# MK65F18 register map
Vendor: NXP Semiconductors; Series: Kinetis_K; File version: 1.6
CPU: CM4 r0p1, little endian, no MPU, FPU, VTOR, 4 interrupt priority bits
Registers are 32-bit, read-write, reset 0x0 unless marked. A register's access mark holds for its fields unless they carry their own. Offsets are from the block's base; [hi:lo] are bit positions; {n}, {i} and the like mark numbered series; 'fields as' and 'values as' point back to an identical list.

## DMAMUX — DMA channel multiplexor
Base 0x40021000; register names take the prefix DMAMUX_
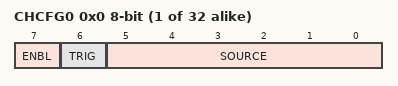
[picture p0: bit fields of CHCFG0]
{0x0+i} CHCFG{i} (i=0..31) 8-bit — Channel Configuration register
  [7] ENBL — DMA Channel Enable
    0=DMA channel is disabled. This mode is primarily used during configuration of the DMAMux. The DMA has separate channel enables/disables, which should be used to disable or reconfigure a DMA channel.; 1=DMA channel is enabled
  [6] TRIG — DMA Channel Trigger Enable
    0=Triggering is disabled. If triggering is disabled and ENBL is set, the DMA Channel will simply route the specified source to the DMA channel. (Normal mode); 1=Triggering is enabled. If triggering is enabled and ENBL is set, the DMAMUX is in Periodic Trigger mode.
  [5:0] SOURCE — DMA Channel Source (Slot)
    0=Disable_Signal; 1=TSI0_Signal; 2=UART0_Rx_Signal; 3=UART0_Tx_Signal; 4=UART1_Rx_Signal; 5=UART1_Tx_Signal; 6=UART2_Rx_Signal; 7=UART2_Tx_Signal; 8=UART3_Rx_Signal; 9=UART3_Tx_Signal; 10=UART4_Signal; 12=I2S0_Rx_Signal; 13=I2S0_Tx_Signal; 14=SPI0_Rx_Signal; 15=SPI0_Tx_Signal; 16=SPI1_Rx_Signal; 17=SPI1_Tx_Signal; 18=I2C0_I2C3_Signal; 19=I2C1_I2C2_Signal; {v}=FTM0_Channel{v-20}_Signal (v=20..27); 28=FTM1_TPM1_Channel0_Signal; 29=FTM1_TPM1_Channel1_Signal; 30=FTM2_TPM2_Channel0_Signal; 31=FTM2_TPM2_Channel1_Signal; {v}=FTM3_Channel{v-32}_Signal (v=32..37); 38=FTM3_Channel6_SPI2_Rx_Signal; 39=FTM3_Channel7_SPI2_Tx_Signal; 40=ADC0_Signal; 41=ADC1_Signal; 42=CMP0_Signal; 43=CMP1_Signal; 44=CMP2_CMP3_Signal; 45=DAC0_Signal; 46=DAC1_Signal; 47=CMT_Signal; 48=PDB_Signal; 49=PortA_Signal; 50=PortB_Signal; 51=PortC_Signal; 52=PortD_Signal; 53=PortE_Signal; 54=IEEE1588Timer0_Signal; 55=IEEE1588Timer1_TPM1_Overflow_Signal; 56=IEEE1588Timer2_TPM2_Overflow_Signal; 57=IEEE1588Timer3_Signal; 58=LPUART0_Rx_Signal; 59=LPUART0_Tx_Signal; {v}=AlwaysOn{v}_Signal (v=60..63)

## CRC — Cyclic Redundancy Check
Base 0x40032000; register names take the prefix CRC_
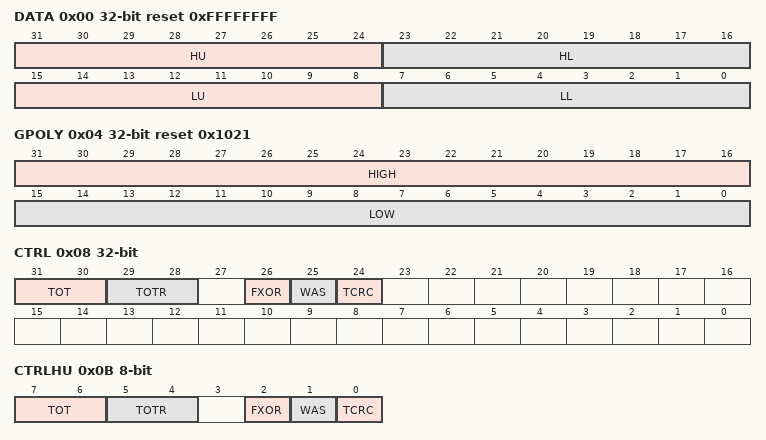
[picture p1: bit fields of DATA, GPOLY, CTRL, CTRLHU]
0x00 DATA reset 0xFFFFFFFF (CRC view) — CRC Data register
  [31:24] HU — CRC High Upper Byte
  [23:16] HL — CRC High Lower Byte
  [15:8] LU — CRC Low Upper Byte
  [7:0] LL — CRC Low Lower Byte
0x00 DATAL 16-bit reset 0xFFFF (CRC view) — CRC_DATAL register.
  [15:0] DATAL — DATAL stores the lower 16 bits of the 16/32 bit CRC
0x00 DATALL 8-bit reset 0xFF (CRC view) — CRC_DATALL register.
  [7:0] DATALL — CRCLL stores the first 8 bits of the 32 bit DATA
0x01 DATALU 8-bit reset 0xFF — CRC_DATALU register.
  [7:0] DATALU — DATALL stores the second 8 bits of the 32 bit CRC
0x02 DATAH 16-bit reset 0xFFFF (CRC view) — CRC_DATAH register.
  [15:0] DATAH — DATAH stores the high 16 bits of the 16/32 bit CRC
0x02 DATAHL 8-bit reset 0xFF (CRC view) — CRC_DATAHL register.
  [7:0] DATAHL — DATAHL stores the third 8 bits of the 32 bit CRC
0x03 DATAHU 8-bit reset 0xFF — CRC_DATAHU register.
  [7:0] DATAHU — DATAHU stores the fourth 8 bits of the 32 bit CRC
0x04 GPOLY reset 0x1021 (CRC view) — CRC Polynomial register
  [31:16] HIGH — High Polynominal Half-word
  [15:0] LOW — Low Polynominal Half-word
0x04 GPOLYL 16-bit reset 0xFFFF (CRC view) — CRC_GPOLYL register.
  [15:0] GPOLYL — POLYL stores the lower 16 bits of the 16/32 bit CRC polynomial value
0x04 GPOLYLL 8-bit reset 0xFF (CRC view) — CRC_GPOLYLL register.
  [7:0] GPOLYLL — POLYLL stores the first 8 bits of the 32 bit CRC
0x05 GPOLYLU 8-bit reset 0xFF — CRC_GPOLYLU register.
  [7:0] GPOLYLU — POLYLL stores the second 8 bits of the 32 bit CRC
0x06 GPOLYH 16-bit reset 0xFFFF (CRC view) — CRC_GPOLYH register.
  [15:0] GPOLYH — POLYH stores the high 16 bits of the 16/32 bit CRC polynomial value
0x06 GPOLYHL 8-bit reset 0xFF (CRC view) — CRC_GPOLYHL register.
  [7:0] GPOLYHL — POLYHL stores the third 8 bits of the 32 bit CRC
0x07 GPOLYHU 8-bit reset 0xFF — CRC_GPOLYHU register.
  [7:0] GPOLYHU — POLYHU stores the fourth 8 bits of the 32 bit CRC
0x08 CTRL — CRC Control register
  [31:30] TOT — Type Of Transpose For Writes
    0=No transposition; 1=Bits in bytes are transposed; bytes are not transposed; 2=Both bits in bytes and bytes are transposed; 3=Only bytes are transposed; no bits in a byte are transposed
  [29:28] TOTR — Type Of Transpose For Read
    values as TOT
  [26] FXOR — Complement Read Of CRC Data Register
    0=No XOR on reading; 1=Invert or complement the read value of the CRC Data register
  [25] WAS — Write CRC Data Register As Seed
    0=Writes to the CRC data register are data values; 1=Writes to the CRC data register are seed values
  [24] TCRC — Width of CRC protocol.
    0=16-bit CRC protocol; 1=32-bit CRC protocol
0x0B CTRLHU 8-bit — CRC_CTRLHU register.
  [7:6] TOT
    0=No Transposition; 1=Bits in bytes are transposed, bytes are not transposed; 2=Both bits in bytes and bytes are transposed; 3=Only bytes are transposed; no bits in a byte are transposed
  [5:4] TOTR
    values as TOT
  [2] FXOR
    0=No XOR on reading; 1=Invert or complement the read value of CRC data register
  [1] WAS
    0=Writes to CRC data register are data values; 1=Writes to CRC data reguster are seed values
  [0] TCRC
    0=16-bit CRC protocol; 1=32-bit CRC protocol
